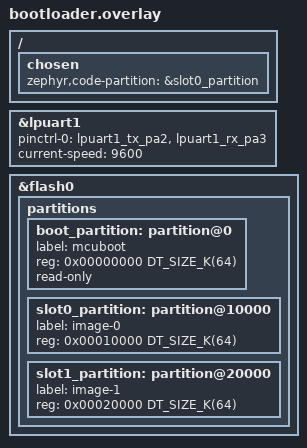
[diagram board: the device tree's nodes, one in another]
/ {
	chosen {
		zephyr,code-partition = &slot0_partition;
	};
};
&lpuart1 {
	pinctrl-0 = <&lpuart1_tx_pa2 &lpuart1_rx_pa3>;
	pinctrl-names = "default";
	current-speed = <9600>;
	status = "okay";
};

/delete-node/ &boot_partition;
/delete-node/ &slot0_partition;
/delete-node/ &slot1_partition;
/delete-node/ &storage_partition;

&flash0 {
	partitions {
		boot_partition: partition@0 {
			label = "mcuboot";
			reg = <0x00000000 DT_SIZE_K(64)>;
			read-only;
		};
		slot0_partition: partition@10000 {
			label = "image-0";
			reg = <0x00010000 DT_SIZE_K(64)>;
		};
		slot1_partition: partition@20000 {
			label = "image-1";
			reg = <0x00020000 DT_SIZE_K(64)>;
		};
	};
};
